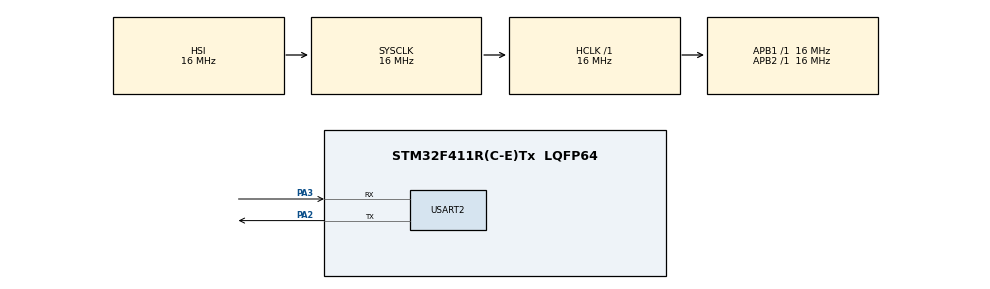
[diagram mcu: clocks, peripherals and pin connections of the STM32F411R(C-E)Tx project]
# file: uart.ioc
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Mcu.Family=STM32F4
Mcu.Name=STM32F411R(C-E)Tx
Mcu.Package=LQFP64
NVIC.PriorityGroup=NVIC_PRIORITYGROUP_4
PA2.Mode=Asynchronous
PA2.Signal=USART2_TX
PA3.Mode=Asynchronous
PA3.Signal=USART2_RX
ProjectManager.HeapSize=0x200
ProjectManager.StackSize=0x400
ProjectManager.TargetToolchain=STM32CubeIDE
RCC.AHBFreq_Value=16000000
RCC.APB1Freq_Value=16000000
RCC.APB2Freq_Value=16000000
RCC.CortexFreq_Value=16000000
RCC.HSE_VALUE=25000000
RCC.HSI_VALUE=16000000
RCC.LSE_VALUE=32768
RCC.SYSCLKFreq_VALUE=16000000
RCC.VCOOutputFreq_Value=192000000
USART2.VirtualMode=VM_ASYNC
board=custom

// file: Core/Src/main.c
/* USER CODE BEGIN Header */
/**
  ******************************************************************************
  * @file           : main.c
  * @brief          : Main program body
  ******************************************************************************
  * @attention
  *
  * Copyright (c) 2024 STMicroelectronics.
  * All rights reserved.
  *
  * This software is licensed under terms that can be found in the LICENSE file
  * in the root directory of this software component.
  * If no LICENSE file comes with this software, it is provided AS-IS.
  *
  ******************************************************************************
  */
/* USER CODE END Header */
#include "main.h"

/* USER CODE BEGIN Includes */
#include <stdio.h>
#include <string.h>
#include <math.h>
/* USER CODE END Includes */

UART_HandleTypeDef huart2;

void SystemClock_Config(void);
static void MX_GPIO_Init(void);
static void MX_USART2_UART_Init(void);

/* USER CODE BEGIN 0 */
int _write(int file, char* p, int len){
	HAL_UART_Transmit(&huart2, (uint8_t*)p, len, 10);
	return len;
}
/* USER CODE END 0 */

int main(void)
{

  /* MCU Configuration--------------------------------------------------------*/

  /* Reset of all peripherals, Initializes the Flash interface and the Systick. */
  HAL_Init();

  /* Configure the system clock */
  SystemClock_Config();

  /* Initialize all configured peripherals */
  MX_GPIO_Init();
  MX_USART2_UART_Init();

  /* Infinite loop */
  /* USER CODE BEGIN WHILE */
  while (1)
  {
//  	char str[] = {"Hello World!\n"};
//  	HAL_UART_Transmit(&huart2, (uint8_t*)str, strlen(str), 1);
//  	HAL_Delay(1000);
//  	printf("Hello World Again!\n");
//  	HAL_Delay(1000);

//  	for(int i=1; i<=1000; i++)
//  		printf("i=%d s=%d\n",i, i%16);
//  	static int angle =0;
//
//  	angle++;
//  	angle %=360;
//  	double sinValue = sin(angle * M_PI / 180);
//  	//printf("angle = %d\n",angle);
//  	printf("%lf\n",sinValue);
//  	HAL_Delay(10);
  	static int comState = 0;
  	static int angleR = 0;
  	static int angleS = 120;
  	static int angleT = 240;
  	angleR++;
  	angleS++;
  	angleT++;
  	angleR%=360;
  	angleS%=360;
  	angleT%=360;
  	float valueR = sin(angleR * M_PI / 180);
  	float valueS = sin(angleS * M_PI / 180);
  	float valueT = sin(angleT * M_PI / 180);

  	if(comState){
  		printf("%f\t",valueR);
			printf("%f\t",valueS);
			printf("%f\n",valueT);
  	}

  	char ch;
  	HAL_StatusTypeDef ret;
  	ret = HAL_UART_Receive(&huart2, &ch, 1, 1);
  	if(ch == '1') comState = 1;
  	if(ch == '0') comState = 0;
  	HAL_Delay(10);

    /* USER CODE END WHILE */

  }
}

void SystemClock_Config(void)
{
  RCC_OscInitTypeDef RCC_OscInitStruct = {0};
  RCC_ClkInitTypeDef RCC_ClkInitStruct = {0};

  /** Configure the main internal regulator output voltage
  */
  __HAL_RCC_PWR_CLK_ENABLE();
  __HAL_PWR_VOLTAGESCALING_CONFIG(PWR_REGULATOR_VOLTAGE_SCALE1);

  /** Initializes the RCC Oscillators according to the specified parameters
  * in the RCC_OscInitTypeDef structure.
  */
  RCC_OscInitStruct.OscillatorType = RCC_OSCILLATORTYPE_HSI;
  RCC_OscInitStruct.HSIState = RCC_HSI_ON;
  RCC_OscInitStruct.HSICalibrationValue = RCC_HSICALIBRATION_DEFAULT;
  RCC_OscInitStruct.PLL.PLLState = RCC_PLL_NONE;
  if (HAL_RCC_OscConfig(&RCC_OscInitStruct) != HAL_OK)
  {
    Error_Handler();
  }

  /** Initializes the CPU, AHB and APB buses clocks
  */
  RCC_ClkInitStruct.ClockType = RCC_CLOCKTYPE_HCLK|RCC_CLOCKTYPE_SYSCLK
                              |RCC_CLOCKTYPE_PCLK1|RCC_CLOCKTYPE_PCLK2;
  RCC_ClkInitStruct.SYSCLKSource = RCC_SYSCLKSOURCE_HSI;
  RCC_ClkInitStruct.AHBCLKDivider = RCC_SYSCLK_DIV1;
  RCC_ClkInitStruct.APB1CLKDivider = RCC_HCLK_DIV1;
  RCC_ClkInitStruct.APB2CLKDivider = RCC_HCLK_DIV1;

  if (HAL_RCC_ClockConfig(&RCC_ClkInitStruct, FLASH_LATENCY_0) != HAL_OK)
  {
    Error_Handler();
  }
}

static void MX_USART2_UART_Init(void)
{

  huart2.Instance = USART2;
  huart2.Init.BaudRate = 115200;
  huart2.Init.WordLength = UART_WORDLENGTH_8B;
  huart2.Init.StopBits = UART_STOPBITS_1;
  huart2.Init.Parity = UART_PARITY_NONE;
  huart2.Init.Mode = UART_MODE_TX_RX;
  huart2.Init.HwFlowCtl = UART_HWCONTROL_NONE;
  huart2.Init.OverSampling = UART_OVERSAMPLING_16;
  if (HAL_UART_Init(&huart2) != HAL_OK)
  {
    Error_Handler();
  }

}

static void MX_GPIO_Init(void)
{

  /* GPIO Ports Clock Enable */
  __HAL_RCC_GPIOA_CLK_ENABLE();

}

void Error_Handler(void)
{
  __disable_irq();
  while (1)
  {
  }
}
